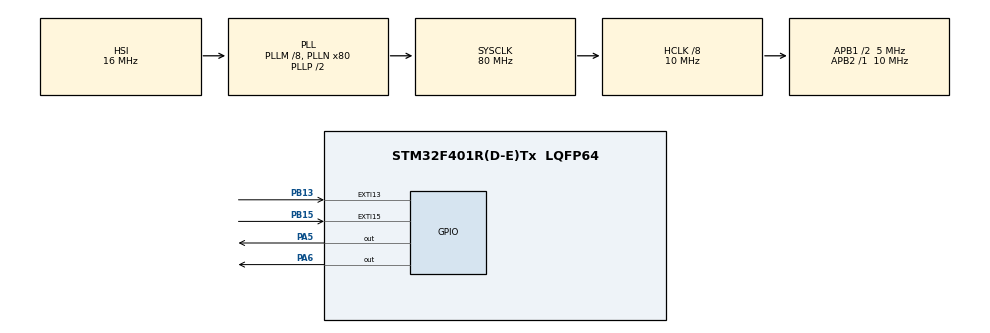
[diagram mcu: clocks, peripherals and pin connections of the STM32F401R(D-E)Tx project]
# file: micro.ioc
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Mcu.Family=STM32F4
Mcu.Name=STM32F401R(D-E)Tx
Mcu.Package=LQFP64
NVIC.EXTI15_10_IRQn=true\:0\:0\:false\:false\:true\:true\:true
NVIC.PriorityGroup=NVIC_PRIORITYGROUP_0
NVIC.TIM1_UP_TIM10_IRQn=true\:0\:0\:false\:false\:true\:true\:true
NVIC.TIM2_IRQn=true\:0\:0\:false\:false\:true\:true\:true
NVIC.TIM3_IRQn=true\:0\:0\:false\:false\:true\:true\:true
PA5.Signal=GPIO_Output
PA6.Signal=GPIO_Output
PB13.GPIO_ModeDefaultEXTI=GPIO_MODE_IT_RISING
PB13.Signal=GPXTI13
PB15.GPIO_ModeDefaultEXTI=GPIO_MODE_IT_RISING
PB15.Signal=GPXTI15
PH0\ -\ OSC_IN.Mode=HSE-External-Oscillator
PH0\ -\ OSC_IN.Signal=RCC_OSC_IN
PH1\ -\ OSC_OUT.Mode=HSE-External-Oscillator
PH1\ -\ OSC_OUT.Signal=RCC_OSC_OUT
ProjectManager.HeapSize=0x200
ProjectManager.StackSize=0x400
ProjectManager.TargetToolchain=EWARM V8
RCC.48MHZClocksFreq_Value=22857142.85714286
RCC.AHBCLKDivider=RCC_SYSCLK_DIV8
RCC.AHBFreq_Value=10000000
RCC.APB1CLKDivider=RCC_HCLK_DIV2
RCC.APB1Freq_Value=5000000
RCC.APB1TimFreq_Value=10000000
RCC.APB2Freq_Value=10000000
RCC.APB2TimFreq_Value=10000000
RCC.CortexFreq_Value=10000000
RCC.HCLKFreq_Value=10000000
RCC.HSE_VALUE=8000000
RCC.HSI_VALUE=16000000
RCC.LSE_VALUE=32768
RCC.PLLM=8
RCC.PLLN=80
RCC.PLLQ=7
RCC.SYSCLKFreq_VALUE=80000000
RCC.SYSCLKSource=RCC_SYSCLKSOURCE_PLLCLK
RCC.VCOOutputFreq_Value=160000000
RTC.Date=12
RTC.Hours=15
RTC.Minutes=45
RTC.Month=RTC_MONTH_JUNE
RTC.Seconds=27
RTC.WeekDay=RTC_WEEKDAY_WEDNESDAY
RTC.Year=19
TIM1.Period=1999
TIM1.Prescaler=49999
TIM2.Period=999
TIM2.Prescaler=4999
TIM3.Period=999
TIM3.Prescaler=0
VP_RTC_VS_RTC_Activate.Mode=RTC_Enabled
VP_RTC_VS_RTC_Calendar.Mode=RTC_Calendar
VP_TIM1_VS_ClockSourceINT.Mode=Internal
VP_TIM2_VS_ClockSourceINT.Mode=Internal
VP_TIM3_VS_ClockSourceINT.Mode=Internal
board=NUCLEO-F401RE

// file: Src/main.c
/* USER CODE BEGIN Header */
/**
  ******************************************************************************
  * @file           : main.c
  * @brief          : Main program body
  ******************************************************************************
  * @attention
  *
  * <h2><center>&copy; Copyright (c) 2019 STMicroelectronics.
  * All rights reserved.</center></h2>
  *
  * This software component is licensed by ST under BSD 3-Clause license,
  * the "License"; You may not use this file except in compliance with the
  * License. You may obtain a copy of the License at:
  *                        opensource.org/licenses/BSD-3-Clause
  *
  ******************************************************************************
  */
/* USER CODE END Header */

#include "main.h"

RTC_HandleTypeDef hrtc;

TIM_HandleTypeDef htim1;
TIM_HandleTypeDef htim2;
TIM_HandleTypeDef htim3;

/* USER CODE BEGIN PV */
RTC_TimeTypeDef sTime = {0};    //RTC_TimeTypeDef to set and store time
RTC_DateTypeDef sDate = {0};    //RTC_DateTypeDef to set and store date

//This varible sets the alert duration in seconds
uint16_t t_timer = 10;  //Setting alarm period in seconds

/* USER CODE END PV */

void SystemClock_Config(void);
static void MX_GPIO_Init(void);
static void MX_TIM1_Init(void);
static void MX_TIM2_Init(void);
static void MX_TIM3_Init(void);
static void MX_RTC_Init(void);

int main(void)
{

  /* MCU Configuration--------------------------------------------------------*/

  /* Reset of all peripherals, Initializes the Flash interface and the Systick. */
  HAL_Init();

  /* Configure the system clock */
  SystemClock_Config();

  /* Initialize all configured peripherals */
  MX_GPIO_Init();
  MX_TIM1_Init();
  MX_TIM2_Init();
  MX_TIM3_Init();
  MX_RTC_Init();
  /* USER CODE BEGIN 2 */

  HAL_RTC_GetTime(&hrtc, &sTime, RTC_FORMAT_BCD);       //Get RTC Time
  HAL_RTC_GetDate(&hrtc, &sDate, RTC_FORMAT_BCD);       //Get RTC Date

  srand(sTime.Seconds);         //Seeded random number generator

  /* USER CODE END 2 */

  /* Infinite loop */
  while (1)
  {

  }
}

void SystemClock_Config(void)
{
  RCC_OscInitTypeDef RCC_OscInitStruct = {0};
  RCC_ClkInitTypeDef RCC_ClkInitStruct = {0};
  RCC_PeriphCLKInitTypeDef PeriphClkInitStruct = {0};

  /** Configure the main internal regulator output voltage
  */
  __HAL_RCC_PWR_CLK_ENABLE();
  __HAL_PWR_VOLTAGESCALING_CONFIG(PWR_REGULATOR_VOLTAGE_SCALE2);
  /** Initializes the CPU, AHB and APB busses clocks
  */
  RCC_OscInitStruct.OscillatorType = RCC_OSCILLATORTYPE_HSI|RCC_OSCILLATORTYPE_LSI;
  RCC_OscInitStruct.HSIState = RCC_HSI_ON;
  RCC_OscInitStruct.HSICalibrationValue = RCC_HSICALIBRATION_DEFAULT;
  RCC_OscInitStruct.LSIState = RCC_LSI_ON;
  RCC_OscInitStruct.PLL.PLLState = RCC_PLL_ON;
  RCC_OscInitStruct.PLL.PLLSource = RCC_PLLSOURCE_HSI;
  RCC_OscInitStruct.PLL.PLLM = 8;
  RCC_OscInitStruct.PLL.PLLN = 80;
  RCC_OscInitStruct.PLL.PLLP = RCC_PLLP_DIV2;
  RCC_OscInitStruct.PLL.PLLQ = 7;
  if (HAL_RCC_OscConfig(&RCC_OscInitStruct) != HAL_OK)
  {
    Error_Handler();
  }
  /** Initializes the CPU, AHB and APB busses clocks
  */
  RCC_ClkInitStruct.ClockType = RCC_CLOCKTYPE_HCLK|RCC_CLOCKTYPE_SYSCLK
                              |RCC_CLOCKTYPE_PCLK1|RCC_CLOCKTYPE_PCLK2;
  RCC_ClkInitStruct.SYSCLKSource = RCC_SYSCLKSOURCE_PLLCLK;
  RCC_ClkInitStruct.AHBCLKDivider = RCC_SYSCLK_DIV8;
  RCC_ClkInitStruct.APB1CLKDivider = RCC_HCLK_DIV2;
  RCC_ClkInitStruct.APB2CLKDivider = RCC_HCLK_DIV1;

  if (HAL_RCC_ClockConfig(&RCC_ClkInitStruct, FLASH_LATENCY_0) != HAL_OK)
  {
    Error_Handler();
  }
  PeriphClkInitStruct.PeriphClockSelection = RCC_PERIPHCLK_RTC;
  PeriphClkInitStruct.RTCClockSelection = RCC_RTCCLKSOURCE_LSI;
  if (HAL_RCCEx_PeriphCLKConfig(&PeriphClkInitStruct) != HAL_OK)
  {
    Error_Handler();
  }
}

static void MX_RTC_Init(void)
{

  /** Initialize RTC Only
  */
  hrtc.Instance = RTC;
  hrtc.Init.HourFormat = RTC_HOURFORMAT_24;
  hrtc.Init.AsynchPrediv = 127;
  hrtc.Init.SynchPrediv = 255;
  hrtc.Init.OutPut = RTC_OUTPUT_DISABLE;
  hrtc.Init.OutPutPolarity = RTC_OUTPUT_POLARITY_HIGH;
  hrtc.Init.OutPutType = RTC_OUTPUT_TYPE_OPENDRAIN;
  if (HAL_RTC_Init(&hrtc) != HAL_OK)
  {
    Error_Handler();
  }

  /** Initialize RTC and set the Time and Date
  */
  sTime.Hours = 0x15;
  sTime.Minutes = 0x45;
  sTime.Seconds = 0x27;
  sTime.DayLightSaving = RTC_DAYLIGHTSAVING_NONE;
  sTime.StoreOperation = RTC_STOREOPERATION_RESET;
  if (HAL_RTC_SetTime(&hrtc, &sTime, RTC_FORMAT_BCD) != HAL_OK)
  {
    Error_Handler();
  }
  sDate.WeekDay = RTC_WEEKDAY_WEDNESDAY;
  sDate.Month = RTC_MONTH_JUNE;
  sDate.Date = 0x12;
  sDate.Year = 0x19;

  if (HAL_RTC_SetDate(&hrtc, &sDate, RTC_FORMAT_BCD) != HAL_OK)
  {
    Error_Handler();
  }

}

static void MX_TIM1_Init(void)
{

  TIM_ClockConfigTypeDef sClockSourceConfig = {0};
  TIM_MasterConfigTypeDef sMasterConfig = {0};

  htim1.Instance = TIM1;
  htim1.Init.Prescaler = 49999;
  htim1.Init.CounterMode = TIM_COUNTERMODE_UP;
  htim1.Init.Period = 200 * t_timer - 1;        //Automatic period calculation
  htim1.Init.ClockDivision = TIM_CLOCKDIVISION_DIV1;
  htim1.Init.RepetitionCounter = 0;
  htim1.Init.AutoReloadPreload = TIM_AUTORELOAD_PRELOAD_DISABLE;
  if (HAL_TIM_Base_Init(&htim1) != HAL_OK)
  {
    Error_Handler();
  }
  sClockSourceConfig.ClockSource = TIM_CLOCKSOURCE_INTERNAL;
  if (HAL_TIM_ConfigClockSource(&htim1, &sClockSourceConfig) != HAL_OK)
  {
    Error_Handler();
  }
  sMasterConfig.MasterOutputTrigger = TIM_TRGO_RESET;
  sMasterConfig.MasterSlaveMode = TIM_MASTERSLAVEMODE_DISABLE;
  if (HAL_TIMEx_MasterConfigSynchronization(&htim1, &sMasterConfig) != HAL_OK)
  {
    Error_Handler();
  }

}

static void MX_TIM2_Init(void)
{

  TIM_ClockConfigTypeDef sClockSourceConfig = {0};
  TIM_MasterConfigTypeDef sMasterConfig = {0};

  htim2.Instance = TIM2;
  htim2.Init.Prescaler = 4999;
  htim2.Init.CounterMode = TIM_COUNTERMODE_UP;
  htim2.Init.Period = 999;
  htim2.Init.ClockDivision = TIM_CLOCKDIVISION_DIV1;
  htim2.Init.AutoReloadPreload = TIM_AUTORELOAD_PRELOAD_DISABLE;
  if (HAL_TIM_Base_Init(&htim2) != HAL_OK)
  {
    Error_Handler();
  }
  sClockSourceConfig.ClockSource = TIM_CLOCKSOURCE_INTERNAL;
  if (HAL_TIM_ConfigClockSource(&htim2, &sClockSourceConfig) != HAL_OK)
  {
    Error_Handler();
  }
  sMasterConfig.MasterOutputTrigger = TIM_TRGO_RESET;
  sMasterConfig.MasterSlaveMode = TIM_MASTERSLAVEMODE_DISABLE;
  if (HAL_TIMEx_MasterConfigSynchronization(&htim2, &sMasterConfig) != HAL_OK)
  {
    Error_Handler();
  }

}

static void MX_TIM3_Init(void)
{

  TIM_ClockConfigTypeDef sClockSourceConfig = {0};
  TIM_MasterConfigTypeDef sMasterConfig = {0};

  htim3.Instance = TIM3;
  htim3.Init.Prescaler = 0;
  htim3.Init.CounterMode = TIM_COUNTERMODE_UP;
  htim3.Init.Period = 999;
  htim3.Init.ClockDivision = TIM_CLOCKDIVISION_DIV1;
  htim3.Init.AutoReloadPreload = TIM_AUTORELOAD_PRELOAD_DISABLE;
  if (HAL_TIM_Base_Init(&htim3) != HAL_OK)
  {
    Error_Handler();
  }
  sClockSourceConfig.ClockSource = TIM_CLOCKSOURCE_INTERNAL;
  if (HAL_TIM_ConfigClockSource(&htim3, &sClockSourceConfig) != HAL_OK)
  {
    Error_Handler();
  }
  sMasterConfig.MasterOutputTrigger = TIM_TRGO_RESET;
  sMasterConfig.MasterSlaveMode = TIM_MASTERSLAVEMODE_DISABLE;
  if (HAL_TIMEx_MasterConfigSynchronization(&htim3, &sMasterConfig) != HAL_OK)
  {
    Error_Handler();
  }

}

static void MX_GPIO_Init(void)
{
  GPIO_InitTypeDef GPIO_InitStruct = {0};

  /* GPIO Ports Clock Enable */
  __HAL_RCC_GPIOH_CLK_ENABLE();
  __HAL_RCC_GPIOA_CLK_ENABLE();
  __HAL_RCC_GPIOB_CLK_ENABLE();

  /*Configure GPIO pin Output Level */
  HAL_GPIO_WritePin(GPIOA, GPIO_PIN_5|GPIO_PIN_6, GPIO_PIN_RESET);

  /*Configure GPIO pins : PA5 PA6 */
  GPIO_InitStruct.Pin = GPIO_PIN_5|GPIO_PIN_6;
  GPIO_InitStruct.Mode = GPIO_MODE_OUTPUT_PP;
  GPIO_InitStruct.Pull = GPIO_NOPULL;
  GPIO_InitStruct.Speed = GPIO_SPEED_FREQ_LOW;
  HAL_GPIO_Init(GPIOA, &GPIO_InitStruct);

  /*Configure GPIO pins : PB13 PB15 */
  GPIO_InitStruct.Pin = GPIO_PIN_13|GPIO_PIN_15;
  GPIO_InitStruct.Mode = GPIO_MODE_IT_RISING;
  GPIO_InitStruct.Pull = GPIO_NOPULL;
  HAL_GPIO_Init(GPIOB, &GPIO_InitStruct);

  /* EXTI interrupt init*/
  HAL_NVIC_SetPriority(EXTI15_10_IRQn, 0, 0);
  HAL_NVIC_EnableIRQ(EXTI15_10_IRQn);

}

void Error_Handler(void)
{
}

/************************ (C) COPYRIGHT STMicroelectronics *****END OF FILE****/
